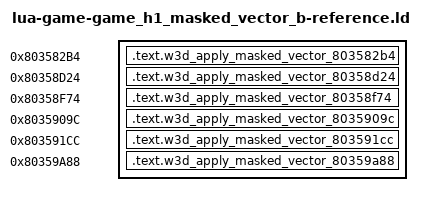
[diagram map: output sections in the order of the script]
/* Generated reference-only placements. All bodies are source-built. */
OUTPUT_FORMAT("elf32-powerpc")
OUTPUT_ARCH(powerpc)
ENTRY(w3d_apply_masked_vector_803582b4)
_SDA_BASE_ = 0x804b2540;
_SDA2_BASE_ = 0x804c2540;
SECTIONS {
  .text.w3d_apply_masked_vector_803582b4 0x803582b4 : { *(.text.w3d_apply_masked_vector_803582b4) }
  .text.w3d_apply_masked_vector_80358d24 0x80358d24 : { *(.text.w3d_apply_masked_vector_80358d24) }
  .text.w3d_apply_masked_vector_80358f74 0x80358f74 : { *(.text.w3d_apply_masked_vector_80358f74) }
  .text.w3d_apply_masked_vector_8035909c 0x8035909c : { *(.text.w3d_apply_masked_vector_8035909c) }
  .text.w3d_apply_masked_vector_803591cc 0x803591cc : { *(.text.w3d_apply_masked_vector_803591cc) }
  .text.w3d_apply_masked_vector_80359a88 0x80359a88 : { *(.text.w3d_apply_masked_vector_80359a88) }
  /DISCARD/ : { *(.text*) *(.rodata*) *(.data*) *(.bss*) *(.sdata*) *(.sbss*) *(.comment) }
}
